AUTOSAR XML (schema 00051)
standard types defined: uint8
package /DataTypes/compuMethods
  compu method cm1: 0=ECU_STATE_STOP, 1=ECU_STATE_START, 2=ECU_STATE_RUN
  compu method cm2: phys=(100+200*raw+300*raw^2)/(1)
package /DataTypes/dataConstrs
  range dc1: raw -128..127
package /Interfaces
  sender receiver interface srif1
    data de1: type=uint8, init-value=1
package /Swcs
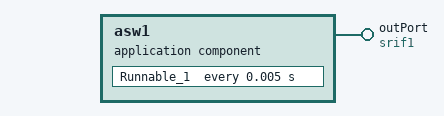
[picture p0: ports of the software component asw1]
  application sw component type asw1
    provide port outPort: provided-interface=srif1
    behavior beh1
      timing event te_5ms: start-on-event=Runnable_1, period=0.005
      runnable Runnable_1: symbol=Run1
        data-send-points:
          access dsp: accessed-variable=outPort.de1
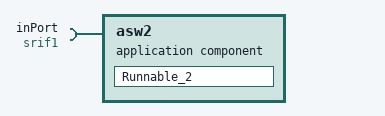
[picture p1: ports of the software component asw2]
  application sw component type asw2
    require port inPort: required-interface=srif1
    behavior beh1
      data received event DRE_Vdp: start-on-event=Runnable_2, data=inPort.de1
      runnable Runnable_2: symbol=Run2
        data-receive-point-by-arguments:
          access dra: accessed-variable=inPort.de1
  composition sw component type Comp
    component asw1_proto: type=asw1
    component asw2_proto: type=asw2
    connect asw1_proto.outPort -> asw2_proto.inPort
package /Can/signals
  i signal sig1: i-signal-type=PRIMITIVE, length=4, system-signal=syssig1
package /Can/systemsignals
  system signal syssig1: dynamic-length=true
package /Can/ecus
  ecu instance ecu1: sleep-mode-supported=false, wake-up-over-bus-supported=true
package /Can/system
  system CanSystem
    system mapping Mappings: sender-receiver-to-signal-mapping{data-element=outPort.de1, system-signal=syssig1}
      sw-mappings:
        swc to ecu mapping SwcMapping: component=rootSwcom.asw1_proto.asw2_proto.asw1_proto, ecu-instance=ecu1
    root-software-compositions:
      root sw composition prototype rootSwcom: software-composition=Comp
package /types
  std cpp implementation data type Array: category=ARRAY, array-size=6, type-emitter=TYPE_EMITTER_ARA
    namespaces:
      symbol props namespace_ns: symbol=ns
